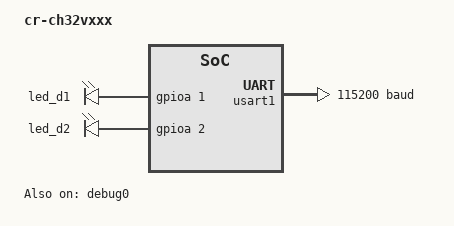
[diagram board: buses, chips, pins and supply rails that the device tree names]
/*
 * Copyright (c) 2024 Michael Hope <michaelh@juju.nz>
 * SPDX-License-Identifier: Apache-2.0
 */

/dts-v1/;

#include <wch/ch32v00x.dtsi>
#include "wch_ch32v003evt-pinctrl.dtsi"

/ {
	model = "cr-ch32vxxx";
	compatible = "wch,ch32v003";

	chosen {
		zephyr,sram = &sram0;
		zephyr,flash = &flash0;
		zephyr,console = &usart1;
		zephyr,shell-uart = &usart1;
	};

	leds {
		compatible = "gpio-leds";

		led_d1: led0 {
			gpios = <&gpioa 1 GPIO_ACTIVE_HIGH>;
		};

		led_d2: led1 {
			gpios = <&gpioa 2 GPIO_ACTIVE_HIGH>;
		};
	};

	aliases {
		led0 = &led_d1;
	};
};

&debug0 {
	status = "okay";
};

&gpiod {
	status = "okay";
};

&usart1 {
	status = "okay";
	current-speed = <115200>;
	pinctrl-0 = <&usart1_default>;
	pinctrl-names = "default";
};
